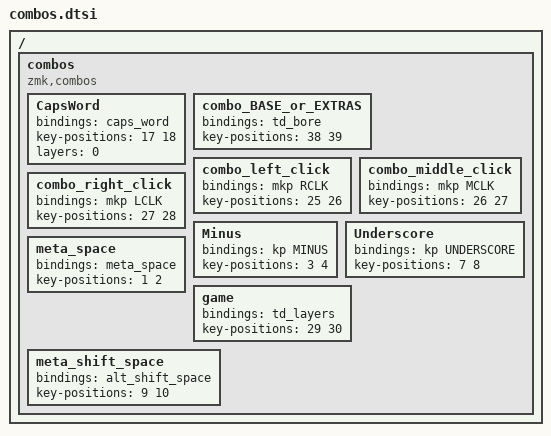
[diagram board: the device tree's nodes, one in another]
/ {
    combos {
        compatible = "zmk,combos";

        CapsWord {
            bindings = <&caps_word>;
            key-positions = <17 18>;
            layers = <0>;
        };

        combo_BASE_or_EXTRAS {
            bindings = <&td_bore>;
            key-positions = <38 39>;
        };

        combo_left_click {
            bindings = <&mkp RCLK>;
            key-positions = <25 26>;
        };

        combo_middle_click {
            bindings = <&mkp MCLK>;
            key-positions = <26 27>;
        };

        combo_right_click {
            bindings = <&mkp LCLK>;
            key-positions = <27 28>;
        };

        Minus {
            bindings = <&kp MINUS>;
            key-positions = <3 4>;
        };

        Underscore {
            bindings = <&kp UNDERSCORE>;
            key-positions = <7 8>;
        };

        meta_space {
            bindings = <&meta_space>;
            key-positions = <1 2>;
        };

        game {
            bindings = <&td_layers>;
            key-positions = <29 30>;
        };

        meta_shift_space {
            bindings = <&alt_shift_space>;
            key-positions = <9 10>;
        };
    };
};
